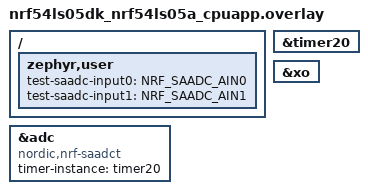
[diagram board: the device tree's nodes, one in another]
/*
 * Copyright (c) 2026 Nordic Semiconductor ASA
 *
 * SPDX-License-Identifier: LicenseRef-Nordic-5-Clause
 */

/ {
	zephyr,user {
		test-saadc-input0 = <NRF_SAADC_AIN0>; /* P1.04 */
		test-saadc-input1 = <NRF_SAADC_AIN1>; /* P1.05 */
	};
};

&timer20 {
	status = "okay";
};

&adc {
	compatible = "nordic,nrf-saadct";
	status = "okay";
	timer-instance = <&timer20>;
	/* Reserve SAADC to ensure that it is assigned to cpuapp and can be used by nrfx_saadc. */
	#address-cells = <1>;
	#size-cells = <0>;
};

&xo {
	status = "okay";
};
